# MB9B160R register map
File version: 1.2
Registers are 8-bit, read-write, reset 0x0 unless marked. A register's access mark holds for its fields unless they carry their own. Offsets are from the block's base; [hi:lo] are bit positions; {n}, {i} and the like mark numbered series; 'fields as' and 'values as' point back to an identical list.

## GPIO — 0
Base 0x4006F000
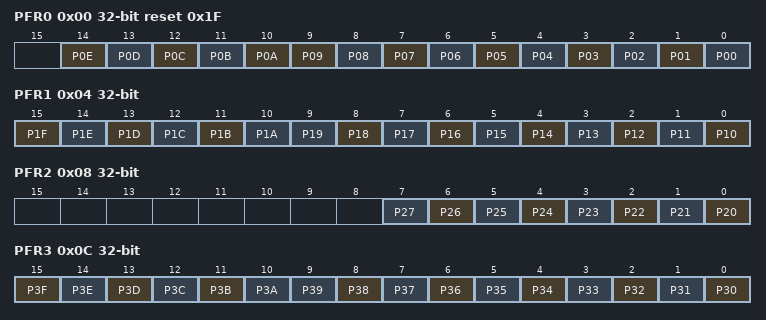
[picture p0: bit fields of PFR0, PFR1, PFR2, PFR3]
0x00 PFR0 32-bit reset 0x1F — Port Function Setting Register 0
  [14] P0E — Bit14 of PFR0
  [13] P0D — Bit13 of PFR0
  [12] P0C — Bit12 of PFR0
  [11] P0B — Bit11 of PFR0
  [10] P0A — Bit10 of PFR0
  [n] P{n:02} (n=0..9) — Bit{n} of PFR0
0x04 PFR1 32-bit — Port Function Setting Register 1
  [15] P1F — Bit15 of PFR1
  [14] P1E — Bit14 of PFR1
  [13] P1D — Bit13 of PFR1
  [12] P1C — Bit12 of PFR1
  [11] P1B — Bit11 of PFR1
  [10] P1A — Bit10 of PFR1
  [n-10] P{n} (n=10..19) — Bit{n-10} of PFR1
0x08 PFR2 32-bit — Port Function Setting Register 2
  [n-20] P{n} (n=20..27) — Bit{n-20} of PFR2
0x0C PFR3 32-bit — Port Function Setting Register 3
  [15] P3F — Bit15 of PFR3
  [14] P3E — Bit14 of PFR3
  [13] P3D — Bit13 of PFR3
  [12] P3C — Bit12 of PFR3
  [11] P3B — Bit11 of PFR3
  [10] P3A — Bit10 of PFR3
  [n-30] P{n} (n=30..39) — Bit{n-30} of PFR3
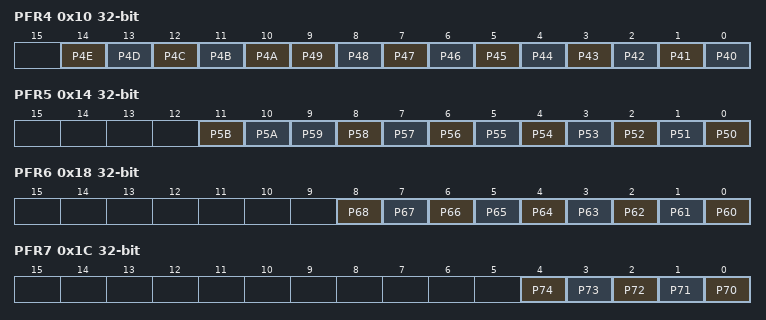
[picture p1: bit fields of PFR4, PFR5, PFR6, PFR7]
0x10 PFR4 32-bit — Port Function Setting Register 4
  [14] P4E — Bit14 of PFR4
  [13] P4D — Bit13 of PFR4
  [12] P4C — Bit12 of PFR4
  [11] P4B — Bit11 of PFR4
  [10] P4A — Bit10 of PFR4
  [n-40] P{n} (n=40..49) — Bit{n-40} of PFR4
0x14 PFR5 32-bit — Port Function Setting Register 5
  [11] P5B — Bit11 of PFR5
  [10] P5A — Bit10 of PFR5
  [n-50] P{n} (n=50..59) — Bit{n-50} of PFR5
0x18 PFR6 32-bit — Port Function Setting Register 6
  [n-60] P{n} (n=60..68) — Bit{n-60} of PFR6
0x1C PFR7 32-bit — Port Function Setting Register 7
  [n-70] P{n} (n=70..74) — Bit{n-70} of PFR7
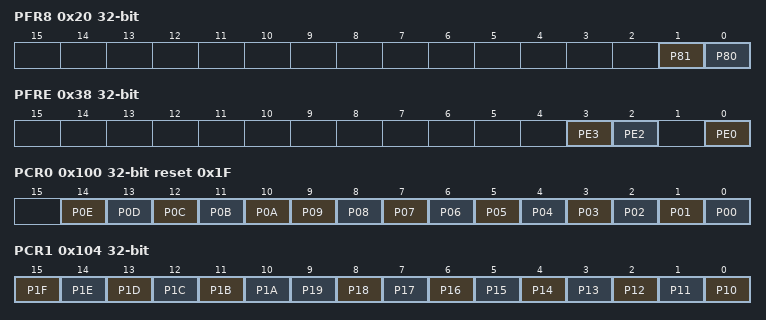
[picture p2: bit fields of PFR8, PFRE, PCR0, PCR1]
0x20 PFR8 32-bit — Port Function Setting Register 8
  [1] P81 — Bit1 of PFR8
  [0] P80 — Bit0 of PFR8
0x38 PFRE 32-bit (reset mask 0xB) — Port Function Setting Register E
  [3] PE3 — Bit3 of PFRE
  [2] PE2 — Bit2 of PFRE
  [0] PE0 — Bit0 of PFRE
0x100 PCR0 32-bit reset 0x1F — Pull-up Setting Register 0
  fields as PFR0
0x104 PCR1 32-bit — Pull-up Setting Register 1
  fields as PFR1
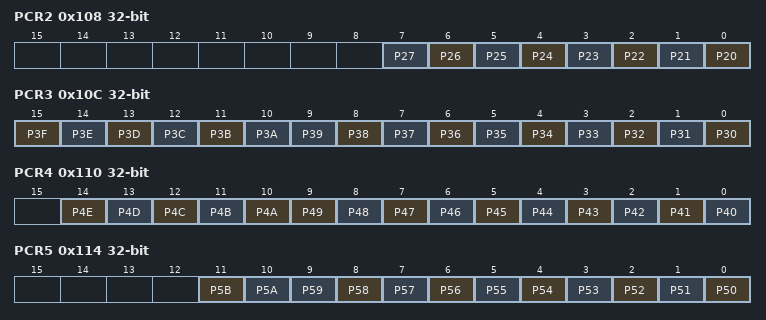
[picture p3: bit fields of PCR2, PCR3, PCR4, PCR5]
0x108 PCR2 32-bit — Pull-up Setting Register 2
  [n-20] P{n} (n=20..27) — Bit{n-20} of PFR2
0x10C PCR3 32-bit — Pull-up Setting Register 3
  fields as PFR3
0x110 PCR4 32-bit — Pull-up Setting Register 4
  fields as PFR4
0x114 PCR5 32-bit — Pull-up Setting Register 5
  fields as PFR5
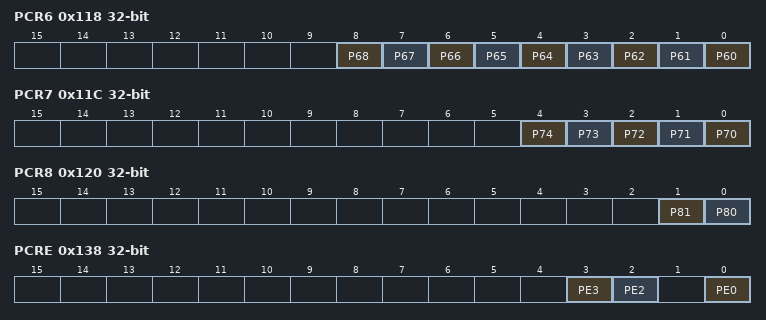
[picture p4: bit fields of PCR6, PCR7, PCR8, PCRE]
0x118 PCR6 32-bit — Pull-up Setting Register 6
  [n-60] P{n} (n=60..68) — Bit{n-60} of PFR6
0x11C PCR7 32-bit — Pull-up Setting Register 7
  [n-70] P{n} (n=70..74) — Bit{n-70} of PFR7
0x120 PCR8 32-bit — Pull-up Setting Register 8
  [1] P81 — Bit1 of PFR8
  [0] P80 — Bit0 of PFR8
0x138 PCRE 32-bit (reset mask 0xB) — Pull-up Setting Register E
  fields as PFRE
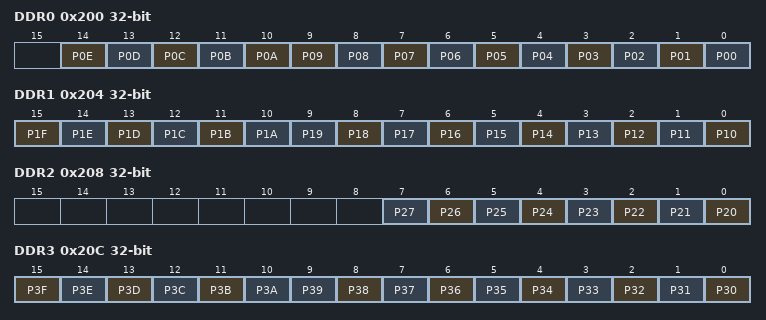
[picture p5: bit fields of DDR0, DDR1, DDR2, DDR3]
0x200 DDR0 32-bit — Port input/output Direction Setting Register 0
  [14] P0E — Bit14 of DDR0
  [13] P0D — Bit13 of DDR0
  [12] P0C — Bit12 of DDR0
  [11] P0B — Bit11 of DDR0
  [10] P0A — Bit10 of DDR0
  [n] P{n:02} (n=0..9) — Bit{n} of DDR0
0x204 DDR1 32-bit — Port input/output Direction Setting Register 1
  fields as PFR1
0x208 DDR2 32-bit — Port input/output Direction Setting Register 2
  [n-20] P{n} (n=20..27) — Bit{n-20} of PFR2
0x20C DDR3 32-bit — Port input/output Direction Setting Register 3
  fields as PFR3
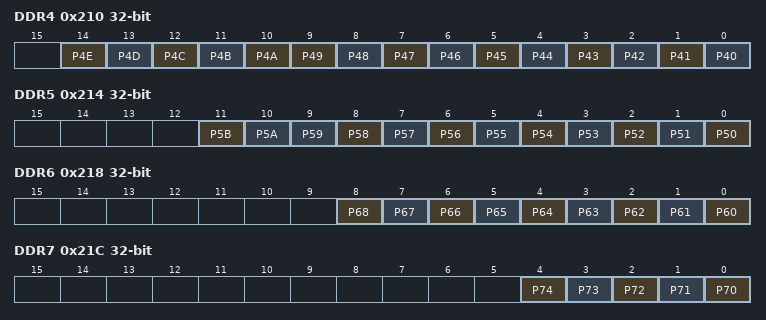
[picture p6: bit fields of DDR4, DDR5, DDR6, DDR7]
0x210 DDR4 32-bit — Port input/output Direction Setting Register 4
  fields as PFR4
0x214 DDR5 32-bit — Port input/output Direction Setting Register 5
  fields as PFR5
0x218 DDR6 32-bit — Port input/output Direction Setting Register 6
  [n-60] P{n} (n=60..68) — Bit{n-60} of PFR6
0x21C DDR7 32-bit — Port input/output Direction Setting Register 7
  [n-70] P{n} (n=70..74) — Bit{n-70} of PFR7
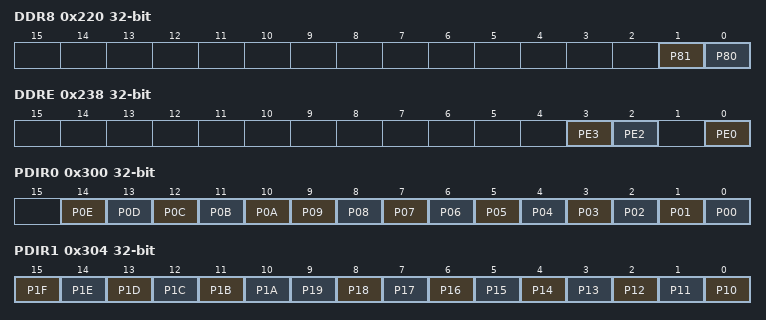
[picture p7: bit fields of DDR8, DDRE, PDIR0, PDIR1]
0x220 DDR8 32-bit — Port input/output Direction Setting Register 8
  [1] P81 — Bit1 of PFR8
  [0] P80 — Bit0 of PFR8
0x238 DDRE 32-bit (reset mask 0xB) — Port input/output Direction Setting Register E
  fields as PFRE
0x300 PDIR0 32-bit — Port Input Data Register 0
  fields as DDR0
0x304 PDIR1 32-bit — Port Input Data Register 1
  fields as PFR1
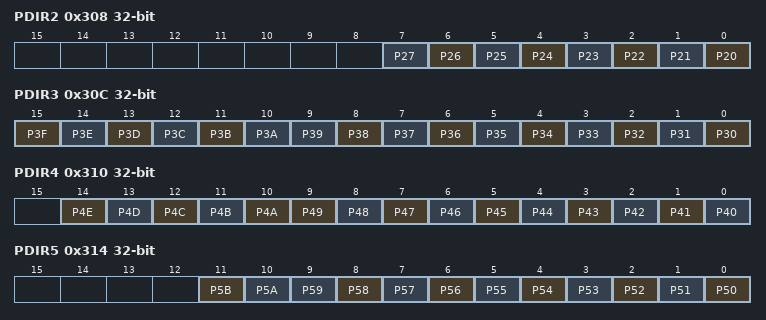
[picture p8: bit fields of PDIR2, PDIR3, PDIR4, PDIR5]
0x308 PDIR2 32-bit — Port Input Data Register 2
  [n-20] P{n} (n=20..27) — Bit{n-20} of PFR2
0x30C PDIR3 32-bit — Port Input Data Register 3
  fields as PFR3
0x310 PDIR4 32-bit — Port Input Data Register 4
  fields as PFR4
0x314 PDIR5 32-bit — Port Input Data Register 5
  fields as PFR5
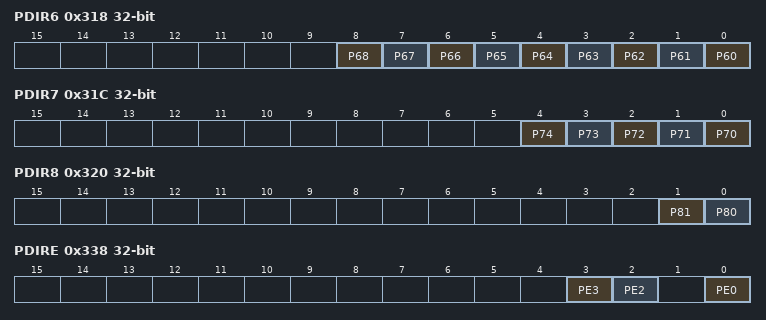
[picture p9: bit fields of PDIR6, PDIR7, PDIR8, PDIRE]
0x318 PDIR6 32-bit — Port Input Data Register 6
  [n-60] P{n} (n=60..68) — Bit{n-60} of PFR6
0x31C PDIR7 32-bit — Port Input Data Register 7
  [n-70] P{n} (n=70..74) — Bit{n-70} of PFR7
0x320 PDIR8 32-bit — Port Input Data Register 8
  [1] P81 — Bit1 of PFR8
  [0] P80 — Bit0 of PFR8
0x338 PDIRE 32-bit (reset mask 0xB) — Port Input Data Register E
  fields as PFRE
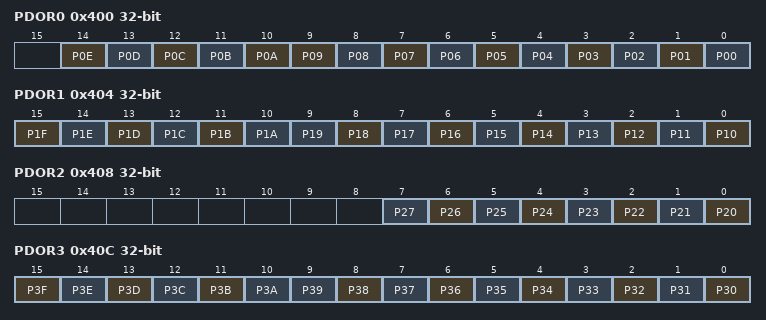
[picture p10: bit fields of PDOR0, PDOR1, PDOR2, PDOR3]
0x400 PDOR0 32-bit — Port Output Data Register 0
  fields as DDR0
0x404 PDOR1 32-bit — Port Output Data Register 1
  fields as PFR1
0x408 PDOR2 32-bit — Port Output Data Register 2
  [n-20] P{n} (n=20..27) — Bit{n-20} of PFR2
0x40C PDOR3 32-bit — Port Output Data Register 3
  fields as PFR3
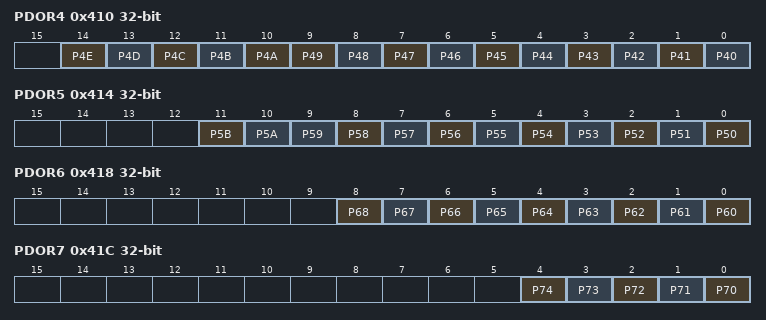
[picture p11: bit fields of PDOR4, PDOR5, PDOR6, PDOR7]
0x410 PDOR4 32-bit — Port Output Data Register 4
  fields as PFR4
0x414 PDOR5 32-bit — Port Output Data Register 5
  fields as PFR5
0x418 PDOR6 32-bit — Port Output Data Register 6
  [n-60] P{n} (n=60..68) — Bit{n-60} of PFR6
0x41C PDOR7 32-bit — Port Output Data Register 7
  [n-70] P{n} (n=70..74) — Bit{n-70} of PFR7
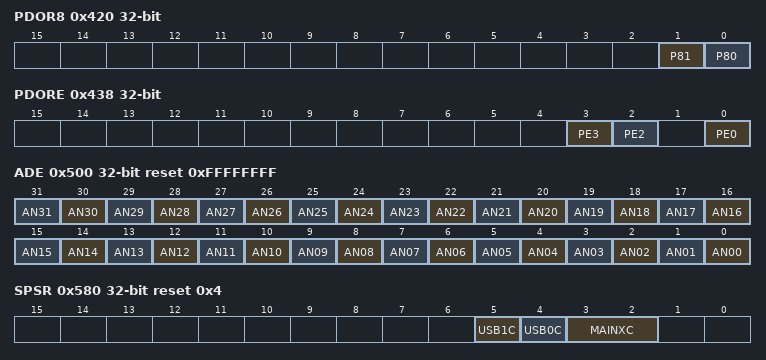
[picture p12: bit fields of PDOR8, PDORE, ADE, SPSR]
0x420 PDOR8 32-bit — Port Output Data Register 8
  [1] P81 — Bit1 of PFR8
  [0] P80 — Bit0 of PFR8
0x438 PDORE 32-bit (reset mask 0xB) — Port Output Data Register E
  fields as PFRE
0x500 ADE 32-bit reset 0xFFFFFFFF — Analog Input Setting Register
  [n] AN{n:02} (n=0..31) — Bit{n} of ADE
0x580 SPSR 32-bit reset 0x4 — Special Port Setting Register
  [5] USB1C — USB (ch.1) Pin Setting bit
  [4] USB0C — USB (ch.0) Pin Setting bit
  [3:2] MAINXC — Main Clock (Oscillation) Pin Setting bits
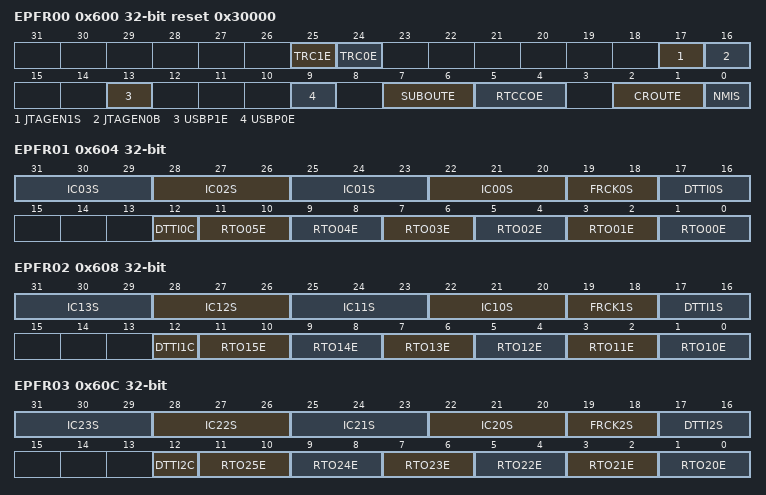
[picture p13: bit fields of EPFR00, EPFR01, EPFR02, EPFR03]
0x600 EPFR00 32-bit reset 0x30000 — Extended Pin Function Setting Register 00
  [25] TRC1E — TRACED Function Select bit 1
  [24] TRC0E — TRACED Function Select bit 0
  [17] JTAGEN1S — JTAG Function Select bit 1
  [16] JTAGEN0B — JTAG Function Select bit 0
  [13] USBP1E — USB ch.1 Function Select bit 1
  [9] USBP0E — USB ch.0 Function Select bit 1
  [7:6] SUBOUTE — Sub clock divide output function select bit
  [5:4] RTCCOE — RTC clock output select bit
  [2:1] CROUTE — Internal high-speed CR Oscillation Output Function Select bit
  [0] NMIS — NMIX Function Select bit
0x604 EPFR01 32-bit — Extended Pin Function Setting Register 01
  [3n+22:3n+20] IC{n:02}S (n=0..3) — IC{n:02} Input Select bits
  [19:18] FRCK0S — FRCK0 Input Select bits
  [17:16] DTTI0S — DTTIX0 Input Select bits
  [12] DTTI0C — DTTIX0 Function Select bit
  [2n+1:2n] RTO{n:02}E (n=0..5) — RTO{n:02} Output Select bits
0x608 EPFR02 32-bit — Extended Pin Function Setting Register 02
  [3n-8:3n-10] IC{n}S (n=10..13) — IC13 Input Select bits
  [19:18] FRCK1S — FRCK1 Input Select bits
  [17:16] DTTI1S — DTTIX1 Input Select bits
  [12] DTTI1C — DTTIX1 Function Select bit
  [2n-19:2n-20] RTO{n}E (n=10..15) — RTO{n} Output Select bits
0x60C EPFR03 32-bit — Extended Pin Function Setting Register 03
  [3n-38:3n-40] IC{n}S (n=20..23) — IC23 Input Select bits
  [19:18] FRCK2S — FRCK2 Input Select bits
  [17:16] DTTI2S — DTTIX2 Input Select bits
  [12] DTTI2C — DTTIX2 Function Select bit
  [2n-39:2n-40] RTO{n}E (n=20..25) — RTO{n} Output Select bits
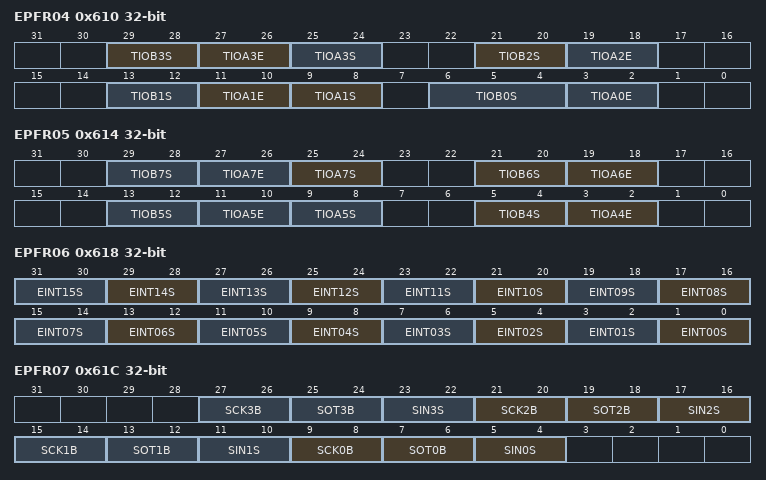
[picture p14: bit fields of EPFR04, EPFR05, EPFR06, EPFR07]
0x610 EPFR04 32-bit — Extended Pin Function Setting Register 04
  [29:28] TIOB3S — TIOB3 Input Select bits
  [8n+3:8n+2] TIOA{n}E (n=0..3) — TIOA{n} Output Select bits
  [25:24] TIOA3S — TIOA3 Input Select bits
  [21:20] TIOB2S — TIOB2 Input Select bits
  [13:12] TIOB1S — TIOB1 Input Select bits
  [9:8] TIOA1S — TIOA1 Input Select bits
  [6:4] TIOB0S — TIOB0 Input Select bits
0x614 EPFR05 32-bit — Extended Pin Function Setting Register 05
  [8n-27:8n-28] TIOB{n}S (n=4..7) — TIOB{n} Input Select bits
  [8n-29:8n-30] TIOA{n}E (n=4..7) — TIOA{n} Output Select bits
  [25:24] TIOA7S — TIOA7 Input Select bits
  [9:8] TIOA5S — TIOA5 Input Select bits
0x618 EPFR06 32-bit — Extended Pin Function Setting Register 06
  [2n+1:2n] EINT{n:02}S (n=0..15) — External Interrupt {n:02} Input Select bits
0x61C EPFR07 32-bit — Extended Pin Function Setting Register 07
  [6n+9:6n+8] SCK{n}B (n=0..3) — SCK{n} Input/Output Select bits
  [6n+7:6n+6] SOT{n}B (n=0..3) — SOT{n} Input/Output Select bits
  [6n+5:6n+4] SIN{n}S (n=0..3) — SIN{n} Input Select bits
0x620 EPFR08 32-bit — Extended Pin Function Setting Register 08
  [31:30] CTS5S — CTS5 Input/Output Select bits
  [29:28] RTS5E — RTS5 Input/Output Select bits
  [6n-15:6n-16] SCK{n}B (n=4..7) — SCK{n} Input/Output Select bits
  [6n-17:6n-18] SOT{n}B (n=4..7) — SOT{n} Input/Output Select bits
  [6n-19:6n-20] SIN{n}S (n=4..7) — SIN{n} Input Select bits
  [3:2] CTS4S — CTS4 Input/Output Select bits
  [1:0] RTS4E — RTS4 Input/Output Select bits
0x624 EPFR09 32-bit — Extended Pin Function Setting Register 09
  [31:30] CTX1E — CTX1E Output Select bits
  [29:28] CRX1S — CRX1S Input Select bits
  [27:26] CTX0E — CTX0E Output Select bits
  [25:24] CRX0S — CRX0S Input Select bits
  [23:20] ADTRG2S — ADTRG2 Input Select bits
  [19:16] ADTRG1S — ADTRG1 Input Select bits
  [15:12] ADTRG0S — ADTRG0 Input Select bits
  [11:10] QZIN1S — QZIN1S Input Select bits
  [9:8] QBIN1S — QBIN1S Input Select bits
  [7:6] QAIN1S — QAIN1S Input Select bits
  [5:4] QZIN0S — QZIN0S Input Select bits
  [3:2] QBIN0S — QBIN0S Input Select bits
  [1:0] QAIN0S — QAIN0S Input Select bits$
0x628 EPFR10 32-bit — Extended Pin Function Setting Register 10
  [n+7] UEA{n:02}E (n=8..24) — UEA{n:02}E Output Select bit
  [14] UEAOOE — UEAOOE Output Select bit
  [n+6] UECS{n}E (n=1..7) — UECS{n}E Output Select bit
  [6] UEFLSE — UEFLSE Output Select bit
  [5] UEOEXE — UEOEXE Output Select bit
  [4] UEDQME — UEDQME Output Select bit
  [3] UEWEXE — UEWEXE Output Select bit
  [2] UECLKE — UECLKE Output Select bit
  [1] UEDTHB — UEDTHB Input/Output Select bit
  [0] UEDEFB — UEDEFB Input/Output Select bit
0x62C EPFR11 32-bit — Extended Pin Function Setting Register 11
  [25] UERLC — UERLC relocation select bit
  [n+9] UED{n:02}B (n=0..15) — UED{n:02}B Input/Output Select bit
  [n+1] UEA{n:02}E (n=1..7) — UEA{n:02}E Output Select bit
  [1] UECS0E — UEA00E Output Select bit
  [0] UEALEE — UEALEE Output Select bit
0x630 EPFR12 32-bit — Extended Pin Function Setting Register 12
  [8n-59:8n-60] TIOB{n}S (n=8..11) — TIOB{n} Input Select bits
  [8n-61:8n-62] TIOA{n}E (n=8..11) — TIOA{n} Output Select bits
  [25:24] TIOA11S — TIOA11 Input Select bits
  [9:8] TIOA9S — TIOA9 Input Select bits
0x634 EPFR13 32-bit — Extended Pin Function Setting Register 13
  [8n-91:8n-92] TIOB{n}S (n=12..15) — TIOB{n} Input Select bits
  [8n-93:8n-94] TIOA{n}E (n=12..15) — TIOA{n} Output Select bits
  [25:24] TIOA15S — TIOA15 Input Select bits
  [9:8] TIOA13S — TIOA13 Input Select bits
0x638 EPFR14 32-bit — Extended Pin Function Setting Register 14
  [29:28] E_SPLC — Input cutoff Select bit in Standby of input Pin for Ethernet-MAC
  [27] E_PSE — PPS0_PPS1 Output Select bit for Ethernet-MAC
  [26] E_CKE — E_COUT Output Select bit
  [25] E_MD1B — E_MDO1 I/O Select bit
  [24] E_MD0B — E_MDO0 I/O Select bit
  [23] E_MC1B — E_MDC1 I/O Select bit
  [22] E_MC0E — E_MDC0 Output Select bit
  [21] E_TE1E — E_TXER0_TXEN1 Output Select bit
  [20] E_TE0E — E_TXEN0 Output Select bit
  [19] E_TD1E — E_TX02_TX10@ E_TX03_TX11 Output Select bit
  [18] E_TD0E — E_TX00@ E_TX01 Output Select bit
  [5:4] QZIN2S — QDU-ch.2 ZIN Input Pin bits
  [3:2] QBIN2S — QDU-ch.2 BIN Input Pin bits
  [1:0] QAIN2S — QDU-ch.2 AIN Input Pin bits
0x63C EPFR15 32-bit — Extended Pin Function Setting Register 15
  [2n-31:2n-32] EINT{n}S (n=16..31) — External Interrupt {n} Input Select bits
0x640 EPFR16 32-bit — Extended Pin Function Setting Register 16
  [29] SFMPBC — MFS ch.B I2C FastMode+ Select bit
  [28] SFMPAC — MFS ch.A I2C FastMode+ Select bit
  [6n-39:6n-40] SCK{n}B (n=8..11) — SCK{n} Input/Output Select bits
  [6n-41:6n-42] SOT{n}B (n=8..11) — SOT{n} Input/Output Select bits
  [6n-43:6n-44] SIN{n}S (n=8..11) — SIN{n} Input Select bits
  [3:2] SCS7B — SCS7 Input/Output Select bits
  [1:0] SCS6B — SCS6 Select bits
0x644 EPFR17 32-bit — Extended Pin Function Setting Register 17
  [6n-63:6n-64] SCK{n}B (n=12..15) — SCK{n} Input/Output Select bits
  [6n-65:6n-66] SOT{n}B (n=12..15) — SOT{n} Input/Output Select bits
  [6n-67:6n-68] SIN{n}S (n=12..15) — SIN{n} Input Select bits
0x648 EPFR18 32-bit — Extended Pin Function Setting Register 18
  [29:28] SDWPS — S_WP input select bits
  [27:26] SDCDS — S_CD input select bits
  [2n+19:2n+18] SDDATA{n}B (n=0..3) — S_CD input select bits
  [17:16] SDCMDB — S_CMD input/output select bits
  [15:14] SDCLKE — S_CLK output select bits
  [9:8] QZIN3S — QDU-ch3 ZIN input select bits
  [7:6] QBIN3S — QDU-ch3 BIN input select bits
  [5:4] QAIN3S — QDU-ch3 AIN input select bits
0x64C EPFR19 32-bit reset not defined — Extended Pin Function Setting Register 19
0x650 EPFR20 32-bit — Extended Pin Function Setting Register 20
  [n-7] UED{n}B (n=16..31) — UED{n}B input/output select bit
  [8] UEDTHHB — UEDTHHB input/output select bit
  [7] UEDQM3E — UEDQM3E output select bit
  [6] UEDQM2E — UEDQM2E output select bit
  [5] UECSXE — UECSXE output select bit
  [4] UEDWEXE — UEDWEXE output select bit
  [3] UECASE — UECASE output select bit
  [2] UERASE — UERASE output select bit
  [1] UESMCEE — UESMCEE output select bit
  [0] UESMCKE — UESMCKE output select bit
0x700 PZR0 32-bit — Port Pseudo Open Drain Setting Register 0
  fields as DDR0
0x704 PZR1 32-bit — Port Pseudo Open Drain Setting Register 1
  fields as PFR1
0x708 PZR2 32-bit — Port Pseudo Open Drain Setting Register 2
  [n-20] P{n} (n=20..27) — Bit{n-20} of PFR2
0x70C PZR3 32-bit — Port Pseudo Open Drain Setting Register 3
  fields as PFR3
0x710 PZR4 32-bit — Port Pseudo Open Drain Setting Register 4
  fields as PFR4
0x714 PZR5 32-bit — Port Pseudo Open Drain Setting Register 5
  fields as PFR5
0x718 PZR6 32-bit — Port Pseudo Open Drain Setting Register 6
  [n-60] P{n} (n=60..68) — Bit{n-60} of PFR6
0x71C PZR7 32-bit — Port Pseudo Open Drain Setting Register 7
  [n-70] P{n} (n=70..74) — Bit{n-70} of PFR7
0x720 PZR8 32-bit — Port Pseudo Open Drain Setting Register 8
  [1] P81 — Bit1 of PFR8
  [0] P80 — Bit0 of PFR8
0x738 PZRE 32-bit (reset mask 0xB) — Port Pseudo Open Drain Setting Register E
  fields as PFRE

## Notices in the file
Copyright (C) 2013 Spansion LLC. All Rights Reserved.
This software is owned and published by:
Spansion LLC, 915 DeGuigne Dr. Sunnyvale, CA  94088-3453 ("Spansion").
BY DOWNLOADING, INSTALLING OR USING THIS SOFTWARE, YOU AGREE TO BE BOUND
BY ALL THE TERMS AND CONDITIONS OF THIS AGREEMENT.
This software contains source code for use with Spansion
components. This software is licensed by Spansion to be adapted only
for use in systems utilizing Spansion components. Spansion shall not be
responsible for misuse or illegal use of this software for devices not
supported herein.  Spansion is providing this software "AS IS" and will
not be responsible for issues arising from incorrect user implementation
of the software.
SPANSION MAKES NO WARRANTY, EXPRESS OR IMPLIED, ARISING BY LAW OR OTHERWISE,
REGARDING THE SOFTWARE (INCLUDING ANY ACOOMPANYING WRITTEN MATERIALS),
ITS PERFORMANCE OR SUITABILITY FOR YOUR INTENDED USE, INCLUDING,
WITHOUT LIMITATION, THE IMPLIED WARRANTY OF MERCHANTABILITY, THE IMPLIED
WARRANTY OF FITNESS FOR A PARTICULAR PURPOSE OR USE, AND THE IMPLIED
WARRANTY OF NONINFRINGEMENT.
SPANSION SHALL HAVE NO LIABILITY (WHETHER IN CONTRACT, WARRANTY, TORT,
NEGLIGENCE OR OTHERWISE) FOR ANY DAMAGES WHATSOEVER (INCLUDING, WITHOUT
LIMITATION, DAMAGES FOR LOSS OF BUSINESS PROFITS, BUSINESS INTERRUPTION,
LOSS OF BUSINESS INFORMATION, OR OTHER PECUNIARY LOSS) ARISING FROM USE OR
INABILITY TO USE THE SOFTWARE, INCLUDING, WITHOUT LIMITATION, ANY DIRECT,
INDIRECT, INCIDENTAL, SPECIAL OR CONSEQUENTIAL DAMAGES OR LOSS OF DATA,
SAVINGS OR PROFITS,
EVEN IF SPANSION HAS BEEN ADVISED OF THE POSSIBILITY OF SUCH DAMAGES.
YOU ASSUME ALL RESPONSIBILITIES FOR SELECTION OF THE SOFTWARE TO ACHIEVE YOUR
INTENDED RESULTS, AND FOR THE INSTALLATION OF, USE OF, AND RESULTS OBTAINED
FROM, THE SOFTWARE.
This software may be replicated in part or whole for the licensed use,
with the restriction that this Disclaimer and Copyright notice must be
included with each copy of this software, whether used in part or whole,
at all times.
